# FM33LG0XX register map
File version: 1.0
CPU: SC000 r1p0, little endian, no MPU, no FPU, 3 interrupt priority bits
Registers are 32-bit, read-write, reset 0x0 unless marked. A register's access mark holds for its fields unless they carry their own. Offsets are from the block's base; [hi:lo] are bit positions.

## CDIF — CDIF module information
Base 0x4001E000
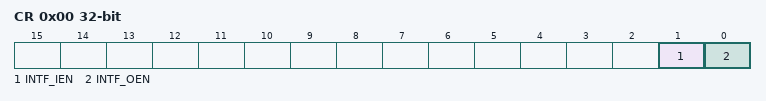
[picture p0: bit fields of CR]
0x00 CR
  [1] INTF_IEN — INTF_IEN field description
  [0] INTF_OEN — INTF_OEN field description
0x04 PRSC
  [2:0] PRSC — PRSC field description

## RMU — RMU module information
Base 0x40002800
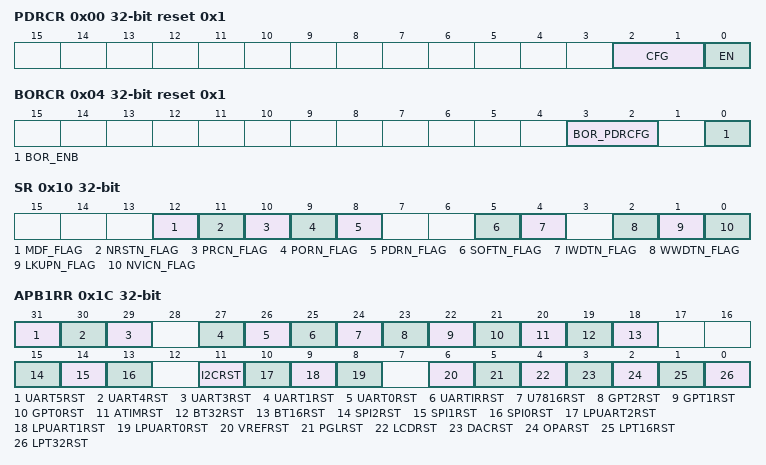
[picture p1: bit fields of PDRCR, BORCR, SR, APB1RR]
0x00 PDRCR reset 0x1 — PDR Control Register
  [2:1] CFG — CFG field description
  [0] EN — EN field description
0x04 BORCR reset 0x1 — BOR Control Register
  [3:2] BOR_PDRCFG — BOR_PDRCFG field description
  [0] BOR_ENB — BOR_ENB field description
0x08 CFGR — Reset Config Register
  [1] EN — EN field description
0x0C SFTRST wo — Software Reset Register
  [31:0] SOFTRST — SOFTRST field description
0x10 SR — Reset Flag Register
  [12] MDF_FLAG — MDF_FLAG field description
  [11] NRSTN_FLAG — NRSTN_FLAG field description
  [10] PRCN_FLAG — PRCN_FLAG field description
  [9] PORN_FLAG — PORN_FLAG field description
  [8] PDRN_FLAG — PDRN_FLAG field description
  [5] SOFTN_FLAG — SOFTN_FLAG field description
  [4] IWDTN_FLAG — IWDTN_FLAG field description
  [2] WWDTN_FLAG — WWDTN_FLAG field description
  [1] LKUPN_FLAG — LKUPN_FLAG field description
  [0] NVICN_FLAG — NVICN_FLAG field description
0x14 PRER wo — Peripheral Reset Enable Register
  [31:0] PERHRSTEN — PERHRSTEN field description
0x18 AHBRR — AHB Peripherals Reset Register
  [0] DMARST — DMARST field description
0x1C APB1RR — APB Peripherals Reset Register1
  [31] UART5RST — UART5RST field description
  [30] UART4RST — UART4RST field description
  [29] UART3RST — UART3RST field description
  [27] UART1RST — UART1RST field description
  [26] UART0RST — UART0RST field description
  [25] UARTIRRST — UARTIRRST field description
  [24] U7816RST — U7816RST field description
  [23] GPT2RST — GPT2RST field description
  [22] GPT1RST — GPT1RST field description
  [21] GPT0RST — GPT0RST field description
  [20] ATIMRST — ATIMRST field description
  [19] BT32RST — BT32RST field description
  [18] BT16RST — BT16RST field description
  [15] SPI2RST — SPI2RST field description
  [14] SPI1RST — SPI1RST field description
  [13] SPI0RST — SPI0RST field description
  [11] I2CRST — I2CRST field description
  [10] LPUART2RST — LPUART2RST field description
  [9] LPUART1RST — LPUART1RST field description
  [8] LPUART0RST — LPUART0RST field description
  [6] VREFRST — VREFRST field description
  [5] PGLRST — PGLRST field description
  [4] LCDRST — LCDRST field description
  [3] DACRST — DACRST field description
  [2] OPARST — OPARST field description
  [1] LPT16RST — LPT16RST field description
  [0] LPT32RST — LPT32RST field description
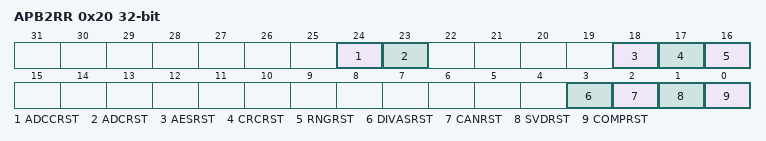
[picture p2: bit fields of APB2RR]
0x20 APB2RR — APB Peripherals Reset Register2
  [24] ADCCRST — ADCCRST field description
  [23] ADCRST — ADCRST field description
  [18] AESRST — AESRST field description
  [17] CRCRST — CRCRST field description
  [16] RNGRST — RNGRST field description
  [3] DIVASRST — DIVASRST field description
  [2] CANRST — CANRST field description
  [1] SVDRST — SVDRST field description
  [0] COMPRST — COMPRST field description

## IWDT — IWDT module information
Base 0x40011400
0x00 SERV wo — IWDT Service Register
  [31:0] SERV — SERV field description
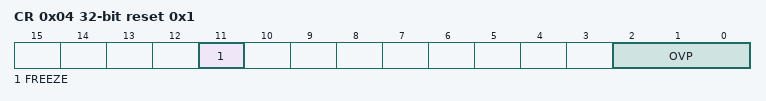
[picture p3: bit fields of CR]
0x04 CR reset 0x1 — IWDT Config Register
  [11] FREEZE — FREEZE field description
  [2:0] OVP — OVP field description
0x08 CNT ro — IWDT Counter Register
  [11:0] CNT — CNT field description
0x0C WIN — IWDT Window Register
  [11:0] WIN — WIN field description
0x10 IER — IWDT Interrupt Enable Register
  [0] IE — IE field description
0x14 ISR — IWDT Interrupt Status Register
  [0] WINF — WINF field description

## WWDT — WWDT module information
Base 0x40011800
0x00 CR wo — WWDT Control Register
  [7:0] CON — CON field description
0x04 CFGR reset 0x3 — WWDT Config Register
  [2:0] CFG — CFG field description
0x08 CNT ro — WWDT Counter Register
  [9:0] CNT — CNT field description
0x0C IER — WWDT Interrupt Enable Register
  [0] IE — IE field description
0x10 ISR — WWDT Interrupt Status Register
  [0] NOVF — NOVF field description
0x14 PSC ro — WWDT Prescaler Register
  [11:0] DIV_CNT — DIV_CNT field description
